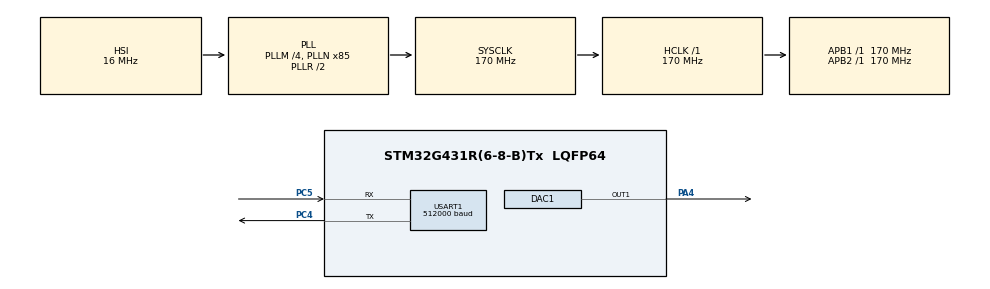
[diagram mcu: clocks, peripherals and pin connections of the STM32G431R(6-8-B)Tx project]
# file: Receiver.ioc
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DAC1.DAC_Trigger_OUT1-DAC_OUT1=DAC_TRIGGER_NONE
Mcu.Family=STM32G4
Mcu.Name=STM32G431R(6-8-B)Tx
Mcu.Package=LQFP64
NVIC.PriorityGroup=NVIC_PRIORITYGROUP_4
NVIC.USART1_IRQn=true\:0\:0\:false\:false\:true\:true\:true\:true
PA4.Signal=COMP_DAC11_group
PC4.Mode=Asynchronous
PC4.Signal=USART1_TX
PC5.Mode=Asynchronous
PC5.Signal=USART1_RX
PF0-OSC_IN.Mode=HSE-External-Oscillator
PF0-OSC_IN.Signal=RCC_OSC_IN
PF1-OSC_OUT.Mode=HSE-External-Oscillator
PF1-OSC_OUT.Signal=RCC_OSC_OUT
ProjectManager.HeapSize=0x200
ProjectManager.StackSize=0x400
ProjectManager.TargetToolchain=STM32CubeIDE
RCC.ADC12Freq_Value=170000000
RCC.AHBFreq_Value=170000000
RCC.APB1Freq_Value=170000000
RCC.APB1TimFreq_Value=170000000
RCC.APB2Freq_Value=170000000
RCC.APB2TimFreq_Value=170000000
RCC.CortexFreq_Value=170000000
RCC.EXTERNAL_CLOCK_VALUE=12288000
RCC.HCLKFreq_Value=170000000
RCC.HSE_VALUE=24000000
RCC.HSI48_VALUE=48000000
RCC.HSI_VALUE=16000000
RCC.LSE_VALUE=32768
RCC.PLLM=RCC_PLLM_DIV4
RCC.PLLN=85
RCC.RTCClockSelection=RCC_RTCCLKSOURCE_LSE
RCC.SYSCLKFreq_VALUE=170000000
RCC.SYSCLKSource=RCC_SYSCLKSOURCE_PLLCLK
RCC.USBFreq_Value=170000000
RCC.VCOOutputFreq_Value=340000000
SH.COMP_DAC11_group.0=DAC1_OUT1,DAC_OUT1
USART1.BaudRate=512000
USART1.VirtualMode-Asynchronous=VM_ASYNC
board=NUCLEO-G431RB

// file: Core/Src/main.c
/* USER CODE BEGIN Header */
/**
  ******************************************************************************
  * @file           : main.c
  * @brief          : Main program body
  ******************************************************************************
  * @attention
  *
  * Copyright (c) 2023 STMicroelectronics.
  * All rights reserved.
  *
  * This software is licensed under terms that can be found in the LICENSE file
  * in the root directory of this software component.
  * If no LICENSE file comes with this software, it is provided AS-IS.
  *
  ******************************************************************************
  */
/* USER CODE END Header */
#include "main.h"

/* USER CODE BEGIN Includes */
//#include "math.h"
/* USER CODE END Includes */

/* USER CODE BEGIN PD */
uint8_t rx_data[2];
uint32_t dac_val;

//uint32_t sine_val[100];
//
//#define PI 3.1415926
//
//void get_sineval()
//{
//	for(int i = 0; i < 100; i++)
//	{
//		sine_val[i] = ((sin(i * 2*PI/100) + 1) * (4096/2));
//	}
//}
/* USER CODE END PD */

DAC_HandleTypeDef hdac1;

UART_HandleTypeDef huart1;

/* USER CODE BEGIN PV */
void HAL_UART_RxCpltCallback(UART_HandleTypeDef *huart){
	dac_val = 0;
	dac_val = ((uint32_t)rx_data[0] << 8) | (uint32_t)rx_data[1];
	//if(j >= 100){
	//	j = 0;
	//}
	HAL_DAC_SetValue(&hdac1, DAC_CHANNEL_1, DAC_ALIGN_12B_R, dac_val);
	//j++;
	HAL_UART_Receive_IT(&huart1, rx_data, sizeof(rx_data));
}
/* USER CODE END PV */

void SystemClock_Config(void);
static void MX_GPIO_Init(void);
static void MX_DAC1_Init(void);
static void MX_USART1_UART_Init(void);

int main(void)
{

  /* MCU Configuration--------------------------------------------------------*/

  /* Reset of all peripherals, Initializes the Flash interface and the Systick. */
  HAL_Init();

  /* Configure the system clock */
  SystemClock_Config();

  /* Initialize all configured peripherals */
  MX_GPIO_Init();
  MX_DAC1_Init();
  MX_USART1_UART_Init();
  /* USER CODE BEGIN 2 */

  HAL_UART_Receive_IT(&huart1, rx_data, sizeof(rx_data));
  HAL_DAC_Start(&hdac1, DAC_CHANNEL_1);
  //get_sineval();
  /* USER CODE END 2 */

  /* Infinite loop */
  while (1)
  {

  }
}

void SystemClock_Config(void)
{
  RCC_OscInitTypeDef RCC_OscInitStruct = {0};
  RCC_ClkInitTypeDef RCC_ClkInitStruct = {0};

  /** Configure the main internal regulator output voltage
  */
  HAL_PWREx_ControlVoltageScaling(PWR_REGULATOR_VOLTAGE_SCALE1_BOOST);

  /** Initializes the RCC Oscillators according to the specified parameters
  * in the RCC_OscInitTypeDef structure.
  */
  RCC_OscInitStruct.OscillatorType = RCC_OSCILLATORTYPE_HSI;
  RCC_OscInitStruct.HSIState = RCC_HSI_ON;
  RCC_OscInitStruct.HSICalibrationValue = RCC_HSICALIBRATION_DEFAULT;
  RCC_OscInitStruct.PLL.PLLState = RCC_PLL_ON;
  RCC_OscInitStruct.PLL.PLLSource = RCC_PLLSOURCE_HSI;
  RCC_OscInitStruct.PLL.PLLM = RCC_PLLM_DIV4;
  RCC_OscInitStruct.PLL.PLLN = 85;
  RCC_OscInitStruct.PLL.PLLP = RCC_PLLP_DIV2;
  RCC_OscInitStruct.PLL.PLLQ = RCC_PLLQ_DIV2;
  RCC_OscInitStruct.PLL.PLLR = RCC_PLLR_DIV2;
  if (HAL_RCC_OscConfig(&RCC_OscInitStruct) != HAL_OK)
  {
    Error_Handler();
  }

  /** Initializes the CPU, AHB and APB buses clocks
  */
  RCC_ClkInitStruct.ClockType = RCC_CLOCKTYPE_HCLK|RCC_CLOCKTYPE_SYSCLK
                              |RCC_CLOCKTYPE_PCLK1|RCC_CLOCKTYPE_PCLK2;
  RCC_ClkInitStruct.SYSCLKSource = RCC_SYSCLKSOURCE_PLLCLK;
  RCC_ClkInitStruct.AHBCLKDivider = RCC_SYSCLK_DIV1;
  RCC_ClkInitStruct.APB1CLKDivider = RCC_HCLK_DIV1;
  RCC_ClkInitStruct.APB2CLKDivider = RCC_HCLK_DIV1;

  if (HAL_RCC_ClockConfig(&RCC_ClkInitStruct, FLASH_LATENCY_4) != HAL_OK)
  {
    Error_Handler();
  }
}

static void MX_DAC1_Init(void)
{

  DAC_ChannelConfTypeDef sConfig = {0};

  /** DAC Initialization
  */
  hdac1.Instance = DAC1;
  if (HAL_DAC_Init(&hdac1) != HAL_OK)
  {
    Error_Handler();
  }

  /** DAC channel OUT1 config
  */
  sConfig.DAC_HighFrequency = DAC_HIGH_FREQUENCY_INTERFACE_MODE_AUTOMATIC;
  sConfig.DAC_DMADoubleDataMode = DISABLE;
  sConfig.DAC_SignedFormat = DISABLE;
  sConfig.DAC_SampleAndHold = DAC_SAMPLEANDHOLD_DISABLE;
  sConfig.DAC_Trigger = DAC_TRIGGER_NONE;
  sConfig.DAC_Trigger2 = DAC_TRIGGER_NONE;
  sConfig.DAC_OutputBuffer = DAC_OUTPUTBUFFER_ENABLE;
  sConfig.DAC_ConnectOnChipPeripheral = DAC_CHIPCONNECT_EXTERNAL;
  sConfig.DAC_UserTrimming = DAC_TRIMMING_FACTORY;
  if (HAL_DAC_ConfigChannel(&hdac1, &sConfig, DAC_CHANNEL_1) != HAL_OK)
  {
    Error_Handler();
  }

}

static void MX_USART1_UART_Init(void)
{

  huart1.Instance = USART1;
  huart1.Init.BaudRate = 512000;
  huart1.Init.WordLength = UART_WORDLENGTH_8B;
  huart1.Init.StopBits = UART_STOPBITS_1;
  huart1.Init.Parity = UART_PARITY_NONE;
  huart1.Init.Mode = UART_MODE_TX_RX;
  huart1.Init.HwFlowCtl = UART_HWCONTROL_NONE;
  huart1.Init.OverSampling = UART_OVERSAMPLING_16;
  huart1.Init.OneBitSampling = UART_ONE_BIT_SAMPLE_DISABLE;
  huart1.Init.ClockPrescaler = UART_PRESCALER_DIV1;
  huart1.AdvancedInit.AdvFeatureInit = UART_ADVFEATURE_NO_INIT;
  if (HAL_UART_Init(&huart1) != HAL_OK)
  {
    Error_Handler();
  }
  if (HAL_UARTEx_SetTxFifoThreshold(&huart1, UART_TXFIFO_THRESHOLD_1_8) != HAL_OK)
  {
    Error_Handler();
  }
  if (HAL_UARTEx_SetRxFifoThreshold(&huart1, UART_RXFIFO_THRESHOLD_1_8) != HAL_OK)
  {
    Error_Handler();
  }
  if (HAL_UARTEx_DisableFifoMode(&huart1) != HAL_OK)
  {
    Error_Handler();
  }

}

static void MX_GPIO_Init(void)
{

  /* GPIO Ports Clock Enable */
  __HAL_RCC_GPIOF_CLK_ENABLE();
  __HAL_RCC_GPIOA_CLK_ENABLE();
  __HAL_RCC_GPIOC_CLK_ENABLE();

}

void Error_Handler(void)
{
  __disable_irq();
  while (1)
  {
  }
}
